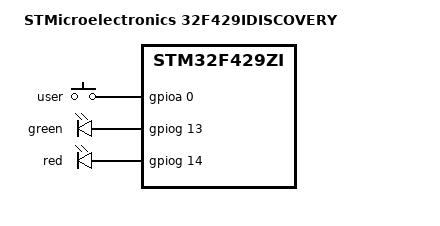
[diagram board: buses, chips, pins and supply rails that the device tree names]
/**
 * \file
 * \brief Devicetree for 32F429IDISCOVERY
 *
 * \author Copyright (C) 2017 Kamil Szczygiel http://www.distortec.com http://www.freddiechopin.info
 *
 * \par License
 * This Source Code Form is subject to the terms of the Mozilla Public License, v. 2.0. If a copy of the MPL was not
 * distributed with this file, You can obtain one at http://mozilla.org/MPL/2.0/.
 */

/dts-v1/;

#include "STM32F429ZI.dtsi"

/ {
	compatible = "ST,32F429IDISCOVERY", "ST,STM32F429ZI";
	model = "STMicroelectronics 32F429IDISCOVERY";

	buttons {
		compatible = "gpio-keys";
		status = "okay";

		b1 {
			gpios = <&gpioa 0 0>;
			label = "user";
			status = "okay";
		};
	};

	leds {
		compatible = "gpio-leds";
		status = "okay";

		ld3 {
			gpios = <&gpiog 13 0>;
			label = "green";
			status = "okay";
		};

		ld4 {
			gpios = <&gpiog 14 0>;
			label = "red";
			status = "okay";
		};
	};

	regulators {
		#address-cells = <1>;
		#size-cells = <0>;

		vdd_regulator: regulator@0 {
			compatible = "fixed-regulator";
			reg = <0>;
			regulator-name = "VDD";
			regulator-min-microvolt = <3000000>;
			regulator-max-microvolt = <3000000>;
			regulator-always-on;
		};
	};
};

&clock_hse {
	clock-frequency = <8000000>;
};

&gpioa {
	status = "okay";
};

&gpiog {
	status = "okay";
};
